AUTOSAR XML (schema 4-1-3)
standard types defined: boolean, sint8, uint16, uint32, uint8, boolean_CompuMethod, boolean_DataConstr, sint8_DataConstr, uint16_DataConstr, uint32_DataConstr, uint8_DataConstr, sint16
package /MICROSAR/Dem_swc/DataTypes
  5 x impl type:
    Dem_DebounceResetStatusType: compu {0=DEM_DEBOUNCE_STATUS_FREEZE, 1=DEM_DEBOUNCE_STATUS_RESET}, range raw 0..255, implementation-data-type=ImplementationDataTypes/uint8
    Dem_DTCFormatType: compu {0=DEM_DTC_FORMAT_OBD, 1=DEM_DTC_FORMAT_UDS, 2=DEM_DTC_FORMAT_J1939}, range raw 0..255, implementation-data-type=ImplementationDataTypes/uint8
    Dem_EventStatusType:
      compu {0=DEM_EVENT_STATUS_PASSED, 1=DEM_EVENT_STATUS_FAILED, 2=DEM_EVENT_STATUS_PREPASSED, 3=DEM_EVENT_STATUS_PREFAILED, 4=DEM_EVENT_STATUS_FDC_THRESHOLD_REACHED, 5=DEM_EVENT_STATUS_PASSED_CONDITIONS_NOT_FULFILLED, 6=DEM_EVENT_STATUS_FAILED_CONDITIONS_NOT_FULFILLED, 7=DEM_EVENT_STATUS_PREPASSED_CONDITIONS_NOT_FULFILLED, 8=DEM_EVENT_STATUS_PREFAILED_CONDITIONS_NOT_FULFILLED}
      range raw 0..255
      implementation-data-type=ImplementationDataTypes/uint8
    Dem_MaxDataValueType: category=ARRAY, sw-calibration-access=READ-ONLY
      element Dem_MaxDataValueTypeElement: array-size=4, array-size-semantics=FIXED-SIZE, implementation-data-type=ImplementationDataTypes/uint8
    Dem_UdsStatusByteType:
      compu {mask 1: 1=DEM_UDS_STATUS_TF (bit 0: TestFailed), mask 2: 2=DEM_UDS_STATUS_TFTOC (bit 1: TestFailedThisOperationCycle), mask 4: 4=DEM_UDS_STATUS_PDTC (bit 2: PendingDTC), mask 8: 8=DEM_UDS_STATUS_CDTC (bit 3: ConfirmedDTC), mask 16: 16=DEM_UDS_STATUS_TNCSLC (bit 4: TestNotCompletedSinceLastClear), mask 32: 32=DEM_UDS_STATUS_TFSLC (bit 5: TestFailedSinceLastClear), mask 64: 64=DEM_UDS_STATUS_TNCTOC (bit 6: TestNotCompletedThisOperationCycle), mask 128: 128=DEM_UDS_STATUS_WIR (bit 7: WarningIndicatorRequested)}
      range raw 0..255
      implementation-data-type=ImplementationDataTypes/uint8
package /MICROSAR/Dem_swc/Interfaces
  client server interface DiagnosticMonitor: is-service=true, service-kind=DIAGNOSTIC-EVENT-MANAGER
    11 x operation:
      GetDTCOfEvent: possible-error=[DEM_E_NO_DTC_AVAILABLE, DiagnosticMonitor/E_NOT_OK]
        arg DTCFormat: type=Dem_DTCFormatType, direction=IN, server-argument-impl-policy=USE-ARGUMENT-TYPE
        arg DTCOfEvent: type=ImplementationDataTypes/uint32, direction=OUT, server-argument-impl-policy=USE-ARGUMENT-TYPE
      GetEventExtendedDataRecordEx: possible-error=[DEM_BUFFER_TOO_SMALL, DEM_NO_SUCH_ELEMENT, DiagnosticMonitor/E_NOT_OK]
        arg RecordNumber: type=ImplementationDataTypes/uint8, direction=IN, server-argument-impl-policy=USE-ARGUMENT-TYPE
        arg DestBuffer: type=Dem_MaxDataValueType, direction=OUT, server-argument-impl-policy=USE-ARGUMENT-TYPE
        arg BufSize: type=ImplementationDataTypes/uint16, direction=INOUT, server-argument-impl-policy=USE-ARGUMENT-TYPE
      GetEventFailed: possible-error=DiagnosticMonitor/E_NOT_OK
        arg EventFailed: type=ImplementationDataTypes/boolean, direction=OUT, server-argument-impl-policy=USE-ARGUMENT-TYPE
      GetEventFreezeFrameDataEx: possible-error=[DEM_BUFFER_TOO_SMALL, DEM_NO_SUCH_ELEMENT, DiagnosticMonitor/E_NOT_OK]
        4 x arg, all with server-argument-impl-policy=USE-ARGUMENT-TYPE:
          RecordNumber: type=ImplementationDataTypes/uint8, direction=IN
          DataId: type=ImplementationDataTypes/uint16, direction=IN
          DestBuffer: type=Dem_MaxDataValueType, direction=OUT
          BufSize: type=ImplementationDataTypes/uint16, direction=INOUT
      GetEventStatus: possible-error=DiagnosticMonitor/E_NOT_OK
        arg UDSStatusByte: type=Dem_UdsStatusByteType, direction=OUT, server-argument-impl-policy=USE-ARGUMENT-TYPE
      GetEventTested: possible-error=DiagnosticMonitor/E_NOT_OK
        arg EventTested: type=ImplementationDataTypes/boolean, direction=OUT, server-argument-impl-policy=USE-ARGUMENT-TYPE
      GetEventUdsStatus: possible-error=DiagnosticMonitor/E_NOT_OK
        arg UDSStatusByte: type=Dem_UdsStatusByteType, direction=OUT, server-argument-impl-policy=USE-ARGUMENT-TYPE
      GetFaultDetectionCounter: possible-error=[DEM_E_NO_FDC_AVAILABLE, DiagnosticMonitor/E_NOT_OK]
        arg FaultDetectionCounter: type=sint8, direction=OUT, server-argument-impl-policy=USE-ARGUMENT-TYPE
      ResetEventDebounceStatus: possible-error=DiagnosticMonitor/E_NOT_OK
        arg DebounceResetStatus: type=Dem_DebounceResetStatusType, direction=IN, server-argument-impl-policy=USE-ARGUMENT-TYPE
      ResetEventStatus: possible-error=DiagnosticMonitor/E_NOT_OK
      SetEventStatus: possible-error=DiagnosticMonitor/E_NOT_OK
        arg EventStatus: type=Dem_EventStatusType, direction=IN, server-argument-impl-policy=USE-ARGUMENT-TYPE
    5 x error:
      DEM_BUFFER_TOO_SMALL: error-code=21
      DEM_E_NO_DTC_AVAILABLE: error-code=10
      DEM_E_NO_FDC_AVAILABLE: error-code=14
      DEM_NO_SUCH_ELEMENT: error-code=48
      E_NOT_OK: error-code=1
package /UAES/ASW/ApplicationDataTypes
  app type Fac_q0p001_u16: category=VALUE, sw-calibration-access=READ-WRITE, compu {phys=raw*0.001}, range phys 0..65.535
package /UAES/ASW/CompuMethods
  compu method CM_boolean: 0=FALSE, 1=TRUE
package /UAES/ASW/DataConstrs
  range DC_boolean: raw 0..1
  range DC_sint16: raw -32768..32767
  range DC_uint16: raw 0..65535
  range DC_uint32: raw 0..4294967295
  range DC_uint8: raw 0..255
package /UAES/ASW/DataTypeMappingSets
  data type mapping set DTMS_SuctnDoor_DD: data-type-map{application-data-type=Fac_q0p001_u16, implementation-data-type=ImplementationDataTypes/uint16}
package /UAES/ASW/PortInterfaces
  5 x client server interface:
    IoHwAb_HbrModCtrl
      operation Hbr_SetMod: possible-error=IoHwAb_HbrModCtrl/E_NOT_OK
        arg id_u16: type=ImplementationDataTypes/uint16, direction=IN, server-argument-impl-policy=USE-ARGUMENT-TYPE
        arg mod_u8: type=ImplementationDataTypes/uint8, direction=IN, server-argument-impl-policy=USE-ARGUMENT-TYPE
      error E_NOT_OK: error-code=1
    IoHwAb_HbrPwm
      operation Hbr_SetDuty: possible-error=IoHwAb_HbrPwm/E_NOT_OK
        arg id_u16: type=ImplementationDataTypes/uint16, direction=IN, server-argument-impl-policy=USE-ARGUMENT-TYPE
        arg duty_u16: type=ImplementationDataTypes/uint16, direction=IN, server-argument-impl-policy=USE-ARGUMENT-TYPE
      operation Hbr_SetPerd: possible-error=IoHwAb_HbrPwm/E_NOT_OK
        arg id_u16: type=ImplementationDataTypes/uint16, direction=IN, server-argument-impl-policy=USE-ARGUMENT-TYPE
        arg perd_u32: type=ImplementationDataTypes/uint32, direction=IN, server-argument-impl-policy=USE-ARGUMENT-TYPE
      operation Hbr_SetPerdAndDuty: possible-error=IoHwAb_HbrPwm/E_NOT_OK
        arg id_u16: type=ImplementationDataTypes/uint16, direction=IN, server-argument-impl-policy=USE-ARGUMENT-TYPE
        arg perd_u32: type=ImplementationDataTypes/uint32, direction=IN, server-argument-impl-policy=USE-ARGUMENT-TYPE
        arg duty_u16: type=ImplementationDataTypes/uint16, direction=IN, server-argument-impl-policy=USE-ARGUMENT-TYPE
      error E_NOT_OK: error-code=1
    IoHwAb_IoDiagHbr
      operation Hbr_Get: possible-error=IoHwAb_IoDiagHbr/E_NOT_OK
        arg id_u16: type=ImplementationDataTypes/uint16, direction=IN, server-argument-impl-policy=USE-ARGUMENT-TYPE
        arg val_u32: type=ImplementationDataTypes/uint32, direction=OUT, server-argument-impl-policy=USE-ARGUMENT-TYPE
      error E_NOT_OK: error-code=1
    IoHwAb_IoSigAdc
      operation Adc_Get: possible-error=IoHwAb_IoSigAdc/E_NOT_OK
        arg id_u16: type=ImplementationDataTypes/uint16, direction=IN, server-argument-impl-policy=USE-ARGUMENT-TYPE
        arg val_s16: type=sint16, direction=OUT, server-argument-impl-policy=USE-ARGUMENT-TYPE
      operation AdcFac_Get: possible-error=IoHwAb_IoSigAdc/E_NOT_OK
        arg id_u16: type=ImplementationDataTypes/uint16, direction=IN, server-argument-impl-policy=USE-ARGUMENT-TYPE
        arg val_s16: type=sint16, direction=OUT, server-argument-impl-policy=USE-ARGUMENT-TYPE
      operation AdcVRMBatt_Get: possible-error=IoHwAb_IoSigAdc/E_NOT_OK
        arg id_u16: type=ImplementationDataTypes/uint16, direction=IN, server-argument-impl-policy=USE-ARGUMENT-TYPE
        arg val_u8: type=ImplementationDataTypes/uint8, direction=OUT, server-argument-impl-policy=USE-ARGUMENT-TYPE
      error E_NOT_OK: error-code=1
    IoHwAb_IoSigDio
      operation Di_Get: possible-error=IoHwAb_IoSigDio/E_NOT_OK
        arg id_u16: type=ImplementationDataTypes/uint16, direction=IN, server-argument-impl-policy=USE-ARGUMENT-TYPE
        arg val_u8: type=ImplementationDataTypes/uint8, direction=OUT, server-argument-impl-policy=USE-ARGUMENT-TYPE
      operation Do_Set: possible-error=IoHwAb_IoSigDio/E_NOT_OK
        arg id_u16: type=ImplementationDataTypes/uint16, direction=IN, server-argument-impl-policy=USE-ARGUMENT-TYPE
        arg val_u8: type=ImplementationDataTypes/uint8, direction=IN, server-argument-impl-policy=USE-ARGUMENT-TYPE
      error E_NOT_OK: error-code=1
  36 x sender receiver interface:
    BattU_buExcdLrgRng: invalidation-policy{data-element=BattU_buExcdLrgRng/Val, handle-invalid=DONT-INVALIDATE}
      data Val: sw-calibration-access=READ-ONLY, type=ImplementationDataTypes/boolean
    BattU_buExcdSmallRng: invalidation-policy{data-element=BattU_buExcdSmallRng/Val, handle-invalid=DONT-INVALIDATE}
      data Val: sw-calibration-access=READ-ONLY, type=ImplementationDataTypes/boolean
    BattU_VrmFac1: invalidation-policy{data-element=BattU_VrmFac1/Val, handle-invalid=DONT-INVALIDATE}
      data Val: sw-calibration-access=READ-ONLY, type=Fac_q0p001_u16
    BattU_VrmFac2: invalidation-policy{data-element=BattU_VrmFac2/Val, handle-invalid=DONT-INVALIDATE}
      data Val: sw-calibration-access=READ-ONLY, type=Fac_q0p001_u16
    BattU_VrmFac3: invalidation-policy{data-element=BattU_VrmFac3/Val, handle-invalid=DONT-INVALIDATE}
      data Val: sw-calibration-access=READ-ONLY, type=Fac_q0p001_u16
    gLock_u8DiagEnbCnd: invalidation-policy{data-element=gLock_u8DiagEnbCnd/Val, handle-invalid=DONT-INVALIDATE}
      data Val: sw-calibration-access=READ-ONLY, type=ImplementationDataTypes/uint8
    gLockCtrl_u8FLDoorElecCinchMotorOutput: invalidation-policy{data-element=gLockCtrl_u8FLDoorElecCinchMotorOutput/Val, handle-invalid=DONT-INVALIDATE}
      data Val: sw-calibration-access=READ-ONLY, type=ImplementationDataTypes/uint8
    gLockCtrl_u8FLDoorElecCinchPWMOutput: invalidation-policy{data-element=gLockCtrl_u8FLDoorElecCinchPWMOutput/Val, handle-invalid=DONT-INVALIDATE}
      data Val: sw-calibration-access=READ-ONLY, type=ImplementationDataTypes/uint8
    gLockCtrl_u8FRDoorElecCinchMotorOutput: invalidation-policy{data-element=gLockCtrl_u8FRDoorElecCinchMotorOutput/Val, handle-invalid=DONT-INVALIDATE}
      data Val: sw-calibration-access=READ-ONLY, type=ImplementationDataTypes/uint8
    gLockCtrl_u8FRDoorElecCinchPWMOutput: invalidation-policy{data-element=gLockCtrl_u8FRDoorElecCinchPWMOutput/Val, handle-invalid=DONT-INVALIDATE}
      data Val: sw-calibration-access=READ-ONLY, type=ImplementationDataTypes/uint8
    gLockCtrl_u8RLDoorElecCinchMotorOutput: invalidation-policy{data-element=gLockCtrl_u8RLDoorElecCinchMotorOutput/Val, handle-invalid=DONT-INVALIDATE}
      data Val: sw-calibration-access=READ-ONLY, type=ImplementationDataTypes/uint8
    gLockCtrl_u8RLDoorElecCinchPWMOutput: invalidation-policy{data-element=gLockCtrl_u8RLDoorElecCinchPWMOutput/Val, handle-invalid=DONT-INVALIDATE}
      data Val: sw-calibration-access=READ-ONLY, type=ImplementationDataTypes/uint8
    gLockCtrl_u8RRDoorElecCinchMotorOutput: invalidation-policy{data-element=gLockCtrl_u8RRDoorElecCinchMotorOutput/Val, handle-invalid=DONT-INVALIDATE}
      data Val: sw-calibration-access=READ-ONLY, type=ImplementationDataTypes/uint8
    gLockCtrl_u8RRDoorElecCinchPWMOutput: invalidation-policy{data-element=gLockCtrl_u8RRDoorElecCinchPWMOutput/Val, handle-invalid=DONT-INVALIDATE}
      data Val: sw-calibration-access=READ-ONLY, type=ImplementationDataTypes/uint8
    gSuctnDoor_bFLCinchMotorMinusSt: invalidation-policy{data-element=gSuctnDoor_bFLCinchMotorMinusSt/Val, handle-invalid=DONT-INVALIDATE}
      data Val: sw-calibration-access=READ-ONLY, type=ImplementationDataTypes/boolean
    gSuctnDoor_bFLCinchMotorPlusSt: invalidation-policy{data-element=gSuctnDoor_bFLCinchMotorPlusSt/Val, handle-invalid=DONT-INVALIDATE}
      data Val: sw-calibration-access=READ-ONLY, type=ImplementationDataTypes/boolean
    gSuctnDoor_bFLCinchReset: invalidation-policy{data-element=gSuctnDoor_bFLCinchReset/Val, handle-invalid=DONT-INVALIDATE}
      data Val: sw-calibration-access=READ-ONLY, type=ImplementationDataTypes/boolean
    gSuctnDoor_bFLInPwrRelsSwt: invalidation-policy{data-element=gSuctnDoor_bFLInPwrRelsSwt/Val, handle-invalid=DONT-INVALIDATE}
      data Val: sw-calibration-access=READ-ONLY, type=ImplementationDataTypes/boolean
    gSuctnDoor_bFLPAWL: invalidation-policy{data-element=gSuctnDoor_bFLPAWL/Val, handle-invalid=DONT-INVALIDATE}
      data Val: sw-calibration-access=READ-ONLY, type=ImplementationDataTypes/boolean
    gSuctnDoor_bFLSecLockFbSt: invalidation-policy{data-element=gSuctnDoor_bFLSecLockFbSt/Val, handle-invalid=DONT-INVALIDATE}
      data Val: sw-calibration-access=READ-ONLY, type=ImplementationDataTypes/boolean
    gSuctnDoor_bFRCinchMotorMinusSt: invalidation-policy{data-element=gSuctnDoor_bFRCinchMotorMinusSt/Val, handle-invalid=DONT-INVALIDATE}
      data Val: sw-calibration-access=READ-ONLY, type=ImplementationDataTypes/boolean
    gSuctnDoor_bFRCinchMotorPlusSt: invalidation-policy{data-element=gSuctnDoor_bFRCinchMotorPlusSt/Val, handle-invalid=DONT-INVALIDATE}
      data Val: sw-calibration-access=READ-ONLY, type=ImplementationDataTypes/boolean
    gSuctnDoor_bFRCinchReset: invalidation-policy{data-element=gSuctnDoor_bFRCinchReset/Val, handle-invalid=DONT-INVALIDATE}
      data Val: sw-calibration-access=READ-ONLY, type=ImplementationDataTypes/boolean
    gSuctnDoor_bFRElecDoorCloseSwt: invalidation-policy{data-element=gSuctnDoor_bFRElecDoorCloseSwt/Val, handle-invalid=DONT-INVALIDATE}
      data Val: sw-calibration-access=READ-ONLY, type=ImplementationDataTypes/boolean
    gSuctnDoor_bFROutPwrRelsSwt: invalidation-policy{data-element=gSuctnDoor_bFROutPwrRelsSwt/Val, handle-invalid=DONT-INVALIDATE}
      data Val: sw-calibration-access=READ-ONLY, type=ImplementationDataTypes/boolean
    gSuctnDoor_bFRPAWL: invalidation-policy{data-element=gSuctnDoor_bFRPAWL/Val, handle-invalid=DONT-INVALIDATE}
      data Val: sw-calibration-access=READ-ONLY, type=ImplementationDataTypes/boolean
    gSuctnDoor_bFRSecLockFbSt: invalidation-policy{data-element=gSuctnDoor_bFRSecLockFbSt/Val, handle-invalid=DONT-INVALIDATE}
      data Val: sw-calibration-access=READ-ONLY, type=ImplementationDataTypes/boolean
    gSuctnDoor_bRLCinchReset: invalidation-policy{data-element=gSuctnDoor_bRLCinchReset/Val, handle-invalid=DONT-INVALIDATE}
      data Val: sw-calibration-access=READ-ONLY, type=ImplementationDataTypes/boolean
    gSuctnDoor_bRLInPwrRelsSwt: invalidation-policy{data-element=gSuctnDoor_bRLInPwrRelsSwt/Val, handle-invalid=DONT-INVALIDATE}
      data Val: sw-calibration-access=READ-ONLY, type=ImplementationDataTypes/boolean
    gSuctnDoor_bRLSecLockFbSt: invalidation-policy{data-element=gSuctnDoor_bRLSecLockFbSt/Val, handle-invalid=DONT-INVALIDATE}
      data Val: sw-calibration-access=READ-ONLY, type=ImplementationDataTypes/boolean
    gSuctnDoor_bRRCinchReset: invalidation-policy{data-element=gSuctnDoor_bRRCinchReset/Val, handle-invalid=DONT-INVALIDATE}
      data Val: sw-calibration-access=READ-ONLY, type=ImplementationDataTypes/boolean
    gSuctnDoor_bRRInPwrRlesSwt: invalidation-policy{data-element=gSuctnDoor_bRRInPwrRlesSwt/Val, handle-invalid=DONT-INVALIDATE}
      data Val: sw-calibration-access=READ-ONLY, type=ImplementationDataTypes/boolean
    gSuctnDoor_bRRSecLockFbSt: invalidation-policy{data-element=gSuctnDoor_bRRSecLockFbSt/Val, handle-invalid=DONT-INVALIDATE}
      data Val: sw-calibration-access=READ-ONLY, type=ImplementationDataTypes/boolean
    gSuctnDoor_u8FLCinchMotorPs: invalidation-policy{data-element=gSuctnDoor_u8FLCinchMotorPs/Val, handle-invalid=DONT-INVALIDATE}
      data Val: sw-calibration-access=READ-ONLY, type=ImplementationDataTypes/uint8
    gSuctnDoor_u8FLElecDoorSwt: invalidation-policy{data-element=gSuctnDoor_u8FLElecDoorSwt/Val, handle-invalid=DONT-INVALIDATE}
      data Val: sw-calibration-access=READ-ONLY, type=ImplementationDataTypes/uint8
    gSuctnDoor_u8FRCinchMotorPs: invalidation-policy{data-element=gSuctnDoor_u8FRCinchMotorPs/Val, handle-invalid=DONT-INVALIDATE}
      data Val: sw-calibration-access=READ-ONLY, type=ImplementationDataTypes/uint8
package /UAES/ASW/SwComponentTypes
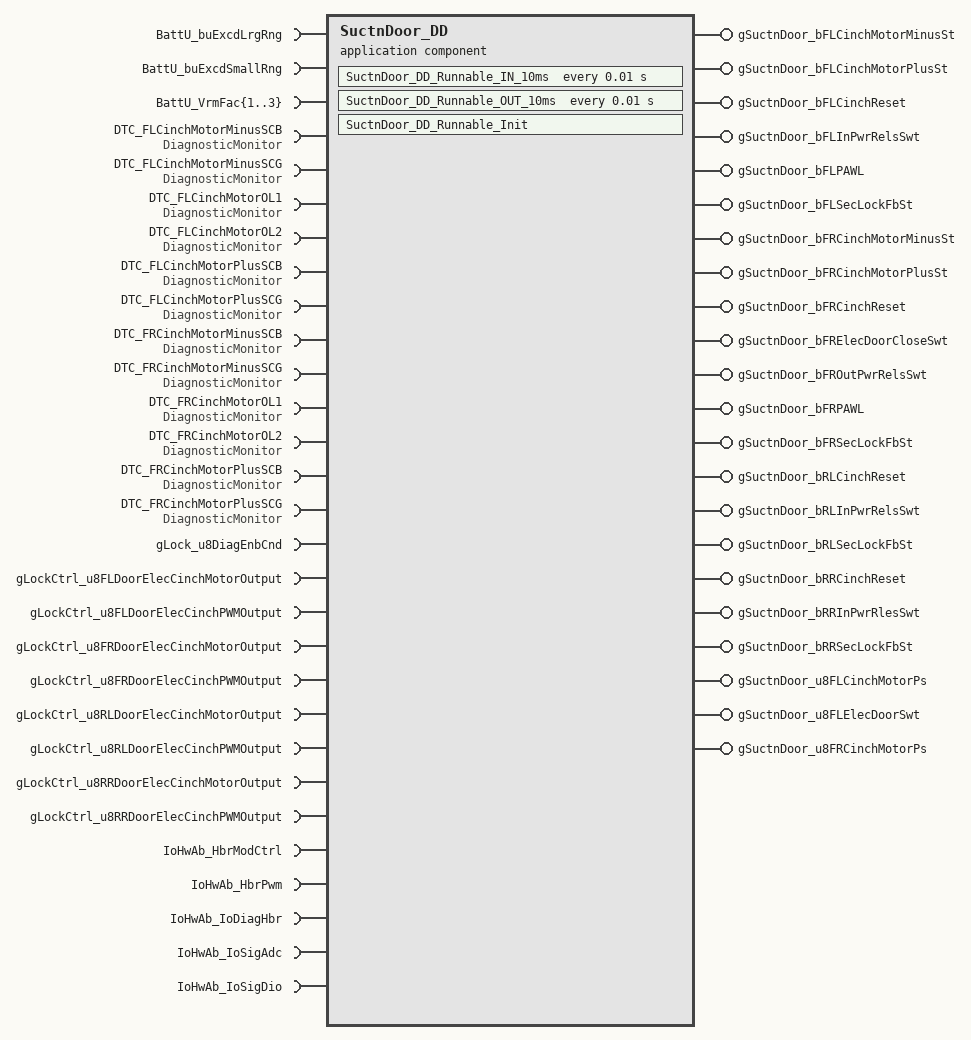
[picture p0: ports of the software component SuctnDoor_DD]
  application sw component type SuctnDoor_DD
    22 x provide port:
      gSuctnDoor_bFLCinchMotorMinusSt: nonqueued-sender-com-spec{data-element=gSuctnDoor_bFLCinchMotorMinusSt/Val, init-value=0}, provided-interface=gSuctnDoor_bFLCinchMotorMinusSt
      gSuctnDoor_bFLCinchMotorPlusSt: nonqueued-sender-com-spec{data-element=gSuctnDoor_bFLCinchMotorPlusSt/Val, init-value=0}, provided-interface=gSuctnDoor_bFLCinchMotorPlusSt
      gSuctnDoor_bFLCinchReset: nonqueued-sender-com-spec{data-element=gSuctnDoor_bFLCinchReset/Val, init-value=0}, provided-interface=gSuctnDoor_bFLCinchReset
      gSuctnDoor_bFLInPwrRelsSwt: nonqueued-sender-com-spec{data-element=gSuctnDoor_bFLInPwrRelsSwt/Val, init-value=0}, provided-interface=gSuctnDoor_bFLInPwrRelsSwt
      gSuctnDoor_bFLPAWL: nonqueued-sender-com-spec{data-element=gSuctnDoor_bFLPAWL/Val, init-value=0}, provided-interface=gSuctnDoor_bFLPAWL
      gSuctnDoor_bFLSecLockFbSt: nonqueued-sender-com-spec{data-element=gSuctnDoor_bFLSecLockFbSt/Val, init-value=0}, provided-interface=gSuctnDoor_bFLSecLockFbSt
      gSuctnDoor_bFRCinchMotorMinusSt: nonqueued-sender-com-spec{data-element=gSuctnDoor_bFRCinchMotorMinusSt/Val, init-value=0}, provided-interface=gSuctnDoor_bFRCinchMotorMinusSt
      gSuctnDoor_bFRCinchMotorPlusSt: nonqueued-sender-com-spec{data-element=gSuctnDoor_bFRCinchMotorPlusSt/Val, init-value=0}, provided-interface=gSuctnDoor_bFRCinchMotorPlusSt
      gSuctnDoor_bFRCinchReset: nonqueued-sender-com-spec{data-element=gSuctnDoor_bFRCinchReset/Val, init-value=0}, provided-interface=gSuctnDoor_bFRCinchReset
      gSuctnDoor_bFRElecDoorCloseSwt: nonqueued-sender-com-spec{data-element=gSuctnDoor_bFRElecDoorCloseSwt/Val, init-value=0}, provided-interface=gSuctnDoor_bFRElecDoorCloseSwt
      gSuctnDoor_bFROutPwrRelsSwt: nonqueued-sender-com-spec{data-element=gSuctnDoor_bFROutPwrRelsSwt/Val, init-value=0}, provided-interface=gSuctnDoor_bFROutPwrRelsSwt
      gSuctnDoor_bFRPAWL: nonqueued-sender-com-spec{data-element=gSuctnDoor_bFRPAWL/Val, init-value=0}, provided-interface=gSuctnDoor_bFRPAWL
      gSuctnDoor_bFRSecLockFbSt: nonqueued-sender-com-spec{data-element=gSuctnDoor_bFRSecLockFbSt/Val, init-value=0}, provided-interface=gSuctnDoor_bFRSecLockFbSt
      gSuctnDoor_bRLCinchReset: nonqueued-sender-com-spec{data-element=gSuctnDoor_bRLCinchReset/Val, init-value=0}, provided-interface=gSuctnDoor_bRLCinchReset
      gSuctnDoor_bRLInPwrRelsSwt: nonqueued-sender-com-spec{data-element=gSuctnDoor_bRLInPwrRelsSwt/Val, init-value=0}, provided-interface=gSuctnDoor_bRLInPwrRelsSwt
      gSuctnDoor_bRLSecLockFbSt: nonqueued-sender-com-spec{data-element=gSuctnDoor_bRLSecLockFbSt/Val, init-value=0}, provided-interface=gSuctnDoor_bRLSecLockFbSt
      gSuctnDoor_bRRCinchReset: nonqueued-sender-com-spec{data-element=gSuctnDoor_bRRCinchReset/Val, init-value=0}, provided-interface=gSuctnDoor_bRRCinchReset
      gSuctnDoor_bRRInPwrRlesSwt: nonqueued-sender-com-spec{data-element=gSuctnDoor_bRRInPwrRlesSwt/Val, init-value=0}, provided-interface=gSuctnDoor_bRRInPwrRlesSwt
      gSuctnDoor_bRRSecLockFbSt: nonqueued-sender-com-spec{data-element=gSuctnDoor_bRRSecLockFbSt/Val, init-value=0}, provided-interface=gSuctnDoor_bRRSecLockFbSt
      gSuctnDoor_u8FLCinchMotorPs: nonqueued-sender-com-spec{data-element=gSuctnDoor_u8FLCinchMotorPs/Val, init-value=0}, provided-interface=gSuctnDoor_u8FLCinchMotorPs
      gSuctnDoor_u8FLElecDoorSwt: nonqueued-sender-com-spec{data-element=gSuctnDoor_u8FLElecDoorSwt/Val, init-value=ComSpec0e782811_d4aa58b4acc01151:0}, provided-interface=gSuctnDoor_u8FLElecDoorSwt
      gSuctnDoor_u8FRCinchMotorPs: nonqueued-sender-com-spec{data-element=gSuctnDoor_u8FRCinchMotorPs/Val, init-value=0}, provided-interface=gSuctnDoor_u8FRCinchMotorPs
    31 x require port:
      BattU_buExcdLrgRng: nonqueued-receiver-com-spec{data-element=BattU_buExcdLrgRng/Val, filter=data-filter-type=ALWAYS, init-value=ComSpec1079bfe5_5cfdb696913237dd:0}, required-interface=BattU_buExcdLrgRng
      BattU_buExcdSmallRng: nonqueued-receiver-com-spec{data-element=BattU_buExcdSmallRng/Val, filter=data-filter-type=ALWAYS, init-value=ComSpecfebe3aa4_0d298b533ebf4b24:0}, required-interface=BattU_buExcdSmallRng
      BattU_VrmFac{1..3}: nonqueued-receiver-com-spec{data-element=BattU_VrmFac{1..3}/Val, filter=data-filter-type=ALWAYS, init-value=0}, required-interface=BattU_VrmFac{1..3}
      DTC_FLCinchMotorMinusSCB: required-interface=DiagnosticMonitor
        required-com-specs:
          GetDTCOfEvent
          GetEventExtendedDataRecordEx
          GetEventFailed
          GetEventFreezeFrameDataEx
          GetEventStatus
          GetEventTested
          GetEventUdsStatus
          GetFaultDetectionCounter
          ResetEventDebounceStatus
          ResetEventStatus
          SetEventStatus
      DTC_FLCinchMotorMinusSCG: required-interface=DiagnosticMonitor
        required-com-specs:
          GetDTCOfEvent
          GetEventExtendedDataRecordEx
          GetEventFailed
          GetEventFreezeFrameDataEx
          GetEventStatus
          GetEventTested
          GetEventUdsStatus
          GetFaultDetectionCounter
          ResetEventDebounceStatus
          ResetEventStatus
          SetEventStatus
      DTC_FLCinchMotorOL1: required-interface=DiagnosticMonitor
        required-com-specs:
          GetDTCOfEvent
          GetEventExtendedDataRecordEx
          GetEventFailed
          GetEventFreezeFrameDataEx
          GetEventStatus
          GetEventTested
          GetEventUdsStatus
          GetFaultDetectionCounter
          ResetEventDebounceStatus
          ResetEventStatus
          SetEventStatus
      DTC_FLCinchMotorOL2: required-interface=DiagnosticMonitor
        required-com-specs:
          GetDTCOfEvent
          GetEventExtendedDataRecordEx
          GetEventFailed
          GetEventFreezeFrameDataEx
          GetEventStatus
          GetEventTested
          GetEventUdsStatus
          GetFaultDetectionCounter
          ResetEventDebounceStatus
          ResetEventStatus
          SetEventStatus
      DTC_FLCinchMotorPlusSCB: required-interface=DiagnosticMonitor
        required-com-specs:
          GetDTCOfEvent
          GetEventExtendedDataRecordEx
          GetEventFailed
          GetEventFreezeFrameDataEx
          GetEventStatus
          GetEventTested
          GetEventUdsStatus
          GetFaultDetectionCounter
          ResetEventDebounceStatus
          ResetEventStatus
          SetEventStatus
      DTC_FLCinchMotorPlusSCG: required-interface=DiagnosticMonitor
        required-com-specs:
          GetDTCOfEvent
          GetEventExtendedDataRecordEx
          GetEventFailed
          GetEventFreezeFrameDataEx
          GetEventStatus
          GetEventTested
          GetEventUdsStatus
          GetFaultDetectionCounter
          ResetEventDebounceStatus
          ResetEventStatus
          SetEventStatus
      DTC_FRCinchMotorMinusSCB: required-interface=DiagnosticMonitor
        required-com-specs:
          GetDTCOfEvent
          GetEventExtendedDataRecordEx
          GetEventFailed
          GetEventFreezeFrameDataEx
          GetEventStatus
          GetEventTested
          GetEventUdsStatus
          GetFaultDetectionCounter
          ResetEventDebounceStatus
          ResetEventStatus
          SetEventStatus
      DTC_FRCinchMotorMinusSCG: required-interface=DiagnosticMonitor
        required-com-specs:
          GetDTCOfEvent
          GetEventExtendedDataRecordEx
          GetEventFailed
          GetEventFreezeFrameDataEx
          GetEventStatus
          GetEventTested
          GetEventUdsStatus
          GetFaultDetectionCounter
          ResetEventDebounceStatus
          ResetEventStatus
          SetEventStatus
      DTC_FRCinchMotorOL1: required-interface=DiagnosticMonitor
        required-com-specs:
          GetDTCOfEvent
          GetEventExtendedDataRecordEx
          GetEventFailed
          GetEventFreezeFrameDataEx
          GetEventStatus
          GetEventTested
          GetEventUdsStatus
          GetFaultDetectionCounter
          ResetEventDebounceStatus
          ResetEventStatus
          SetEventStatus
      DTC_FRCinchMotorOL2: required-interface=DiagnosticMonitor
        required-com-specs:
          GetDTCOfEvent
          GetEventExtendedDataRecordEx
          GetEventFailed
          GetEventFreezeFrameDataEx
          GetEventStatus
          GetEventTested
          GetEventUdsStatus
          GetFaultDetectionCounter
          ResetEventDebounceStatus
          ResetEventStatus
          SetEventStatus
      DTC_FRCinchMotorPlusSCB: required-interface=DiagnosticMonitor
        required-com-specs:
          GetDTCOfEvent
          GetEventExtendedDataRecordEx
          GetEventFailed
          GetEventFreezeFrameDataEx
          GetEventStatus
          GetEventTested
          GetEventUdsStatus
          GetFaultDetectionCounter
          ResetEventDebounceStatus
          ResetEventStatus
          SetEventStatus
      DTC_FRCinchMotorPlusSCG: required-interface=DiagnosticMonitor
        required-com-specs:
          GetDTCOfEvent
          GetEventExtendedDataRecordEx
          GetEventFailed
          GetEventFreezeFrameDataEx
          GetEventStatus
          GetEventTested
          GetEventUdsStatus
          GetFaultDetectionCounter
          ResetEventDebounceStatus
          ResetEventStatus
          SetEventStatus
      gLock_u8DiagEnbCnd: nonqueued-receiver-com-spec{data-element=gLock_u8DiagEnbCnd/Val, filter=data-filter-type=ALWAYS, init-value=0}, required-interface=gLock_u8DiagEnbCnd
      gLockCtrl_u8FLDoorElecCinchMotorOutput: nonqueued-receiver-com-spec{data-element=gLockCtrl_u8FLDoorElecCinchMotorOutput/Val, filter=data-filter-type=ALWAYS, init-value=0}, required-interface=gLockCtrl_u8FLDoorElecCinchMotorOutput
      gLockCtrl_u8FLDoorElecCinchPWMOutput: nonqueued-receiver-com-spec{data-element=gLockCtrl_u8FLDoorElecCinchPWMOutput/Val, filter=data-filter-type=ALWAYS, init-value=0}, required-interface=gLockCtrl_u8FLDoorElecCinchPWMOutput
      gLockCtrl_u8FRDoorElecCinchMotorOutput: nonqueued-receiver-com-spec{data-element=gLockCtrl_u8FRDoorElecCinchMotorOutput/Val, filter=data-filter-type=ALWAYS, init-value=0}, required-interface=gLockCtrl_u8FRDoorElecCinchMotorOutput
      gLockCtrl_u8FRDoorElecCinchPWMOutput: nonqueued-receiver-com-spec{data-element=gLockCtrl_u8FRDoorElecCinchPWMOutput/Val, filter=data-filter-type=ALWAYS, init-value=0}, required-interface=gLockCtrl_u8FRDoorElecCinchPWMOutput
      gLockCtrl_u8RLDoorElecCinchMotorOutput: nonqueued-receiver-com-spec{data-element=gLockCtrl_u8RLDoorElecCinchMotorOutput/Val, filter=data-filter-type=ALWAYS, init-value=0}, required-interface=gLockCtrl_u8RLDoorElecCinchMotorOutput
      gLockCtrl_u8RLDoorElecCinchPWMOutput: nonqueued-receiver-com-spec{data-element=gLockCtrl_u8RLDoorElecCinchPWMOutput/Val, filter=data-filter-type=ALWAYS, init-value=0}, required-interface=gLockCtrl_u8RLDoorElecCinchPWMOutput
      gLockCtrl_u8RRDoorElecCinchMotorOutput: nonqueued-receiver-com-spec{data-element=gLockCtrl_u8RRDoorElecCinchMotorOutput/Val, filter=data-filter-type=ALWAYS, init-value=0}, required-interface=gLockCtrl_u8RRDoorElecCinchMotorOutput
      gLockCtrl_u8RRDoorElecCinchPWMOutput: nonqueued-receiver-com-spec{data-element=gLockCtrl_u8RRDoorElecCinchPWMOutput/Val, filter=data-filter-type=ALWAYS, init-value=0}, required-interface=gLockCtrl_u8RRDoorElecCinchPWMOutput
      IoHwAb_HbrModCtrl: client-com-spec=Hbr_SetMod, required-interface=IoHwAb_HbrModCtrl
      IoHwAb_HbrPwm: required-com-specs=[Hbr_SetDuty, Hbr_SetPerd, Hbr_SetPerdAndDuty], required-interface=IoHwAb_HbrPwm
      IoHwAb_IoDiagHbr: client-com-spec=Hbr_Get, required-interface=IoHwAb_IoDiagHbr
      IoHwAb_IoSigAdc: required-com-specs=[Adc_Get, AdcFac_Get, AdcVRMBatt_Get], required-interface=IoHwAb_IoSigAdc
      IoHwAb_IoSigDio: required-com-specs=[Di_Get, Do_Set], required-interface=IoHwAb_IoSigDio
    behavior SuctnDoor_DD_InternalBehavior: data-type-mapping=DTMS_SuctnDoor_DD
      timing event TMT_SuctnDoor_DD_Runnable_IN_10ms: start-on-event=SuctnDoor_DD_Runnable_IN_10ms, period=0.01
      init event SuctnDoor_DD_InitEvent: start-on-event=SuctnDoor_DD_Runnable_Init
      timing event TMT_SuctnDoor_DD_Runnable_OUT_10ms: start-on-event=SuctnDoor_DD_Runnable_OUT_10ms, period=0.01
      runnable SuctnDoor_DD_Runnable_IN_10ms
        data-receive-point-by-arguments:
          5 x access:
            IN_BattU_buExcdSmallRng_Val: accessed-variable=BattU_buExcdSmallRng.Val
            IN_BattU_VrmFac{1..3}_Val: accessed-variable=BattU_VrmFac{1..3}.Val
            REC_BattU_buExcdLrgRng_Val: accessed-variable=BattU_buExcdLrgRng.Val
        data-send-points:
          16 x access:
            SEND_gSuctnDoor_bFLCinchReset_Val: accessed-variable=gSuctnDoor_bFLCinchReset.Val
            SEND_gSuctnDoor_bFLInPwrRelsSwt_Val: accessed-variable=gSuctnDoor_bFLInPwrRelsSwt.Val
            SEND_gSuctnDoor_bFLPAWL_Val: accessed-variable=gSuctnDoor_bFLPAWL.Val
            SEND_gSuctnDoor_bFLSecLockFbSt_Val: accessed-variable=gSuctnDoor_bFLSecLockFbSt.Val
            SEND_gSuctnDoor_bFRCinchReset_Val: accessed-variable=gSuctnDoor_bFRCinchReset.Val
            SEND_gSuctnDoor_bFRElecDoorCloseSwt_Val: accessed-variable=gSuctnDoor_bFRElecDoorCloseSwt.Val
            SEND_gSuctnDoor_bFROutPwrRelsSwt_Val: accessed-variable=gSuctnDoor_bFROutPwrRelsSwt.Val
            SEND_gSuctnDoor_bFRPAWL_Val: accessed-variable=gSuctnDoor_bFRPAWL.Val
            SEND_gSuctnDoor_bFRSecLockFbSt_Val: accessed-variable=gSuctnDoor_bFRSecLockFbSt.Val
            SEND_gSuctnDoor_bRLCinchReset_Val: accessed-variable=gSuctnDoor_bRLCinchReset.Val
            SEND_gSuctnDoor_bRLInPwrRelsSwt_Val: accessed-variable=gSuctnDoor_bRLInPwrRelsSwt.Val
            SEND_gSuctnDoor_bRLSecLockFbSt_Val: accessed-variable=gSuctnDoor_bRLSecLockFbSt.Val
            SEND_gSuctnDoor_bRRCinchReset_Val: accessed-variable=gSuctnDoor_bRRCinchReset.Val
            SEND_gSuctnDoor_bRRInPwrRlesSwt_Val: accessed-variable=gSuctnDoor_bRRInPwrRlesSwt.Val
            SEND_gSuctnDoor_bRRSecLockFbSt_Val: accessed-variable=gSuctnDoor_bRRSecLockFbSt.Val
            SEND_gSuctnDoor_u8FLElecDoorSwt_Val: accessed-variable=gSuctnDoor_u8FLElecDoorSwt.Val
        sync call SC_IoHwAb_IoSigAdc_AdcFac_Get: operation=IoHwAb_IoSigAdc.AdcFac_Get, timeout=0
        sync call SC_IoHwAb_IoSigAdc_AdcVRMBatt_Get: operation=IoHwAb_IoSigAdc.AdcVRMBatt_Get, timeout=0
        sync call SC_IoHwAb_IoSigDio_Di_Get: operation=IoHwAb_IoSigDio.Di_Get, timeout=0
      runnable SuctnDoor_DD_Runnable_Init
      runnable SuctnDoor_DD_Runnable_OUT_10ms
        data-receive-point-by-arguments:
          9 x access:
            REC_gLock_u8DiagEnaCnd_Val: accessed-variable=gLock_u8DiagEnbCnd.Val
            REC_gLockCtrl_u8FLDoorElecCinchMotorOutput_Val: accessed-variable=gLockCtrl_u8FLDoorElecCinchMotorOutput.Val
            REC_gLockCtrl_u8FLDoorElecCinchPWMOutput_Val: accessed-variable=gLockCtrl_u8FLDoorElecCinchPWMOutput.Val
            REC_gLockCtrl_u8FRDoorElecCinchMotorOutput_Val: accessed-variable=gLockCtrl_u8FRDoorElecCinchMotorOutput.Val
            REC_gLockCtrl_u8FRDoorElecCinchPWMOutput_Val: accessed-variable=gLockCtrl_u8FRDoorElecCinchPWMOutput.Val
            REC_gLockCtrl_u8RLDoorElecCinchMotorOutput_Val: accessed-variable=gLockCtrl_u8RLDoorElecCinchMotorOutput.Val
            REC_gLockCtrl_u8RLDoorElecCinchPWMOutput_Val: accessed-variable=gLockCtrl_u8RLDoorElecCinchPWMOutput.Val
            REC_gLockCtrl_u8RRDoorElecCinchMotorOutput_Val: accessed-variable=gLockCtrl_u8RRDoorElecCinchMotorOutput.Val
            REC_gLockCtrl_u8RRDoorElecCinchPWMOutput_Val: accessed-variable=gLockCtrl_u8RRDoorElecCinchPWMOutput.Val
        data-send-points:
          6 x access:
            SEND_gSuctnDoor_bFLCinchMotorMinusSt_Val: accessed-variable=gSuctnDoor_bFLCinchMotorMinusSt.Val
            SEND_gSuctnDoor_bFLCinchMotorPlusSt_Val: accessed-variable=gSuctnDoor_bFLCinchMotorPlusSt.Val
            SEND_gSuctnDoor_bFRCinchMotorMinusSt_Val: accessed-variable=gSuctnDoor_bFRCinchMotorMinusSt.Val
            SEND_gSuctnDoor_bFRCinchMotorPlusSt_Val: accessed-variable=gSuctnDoor_bFRCinchMotorPlusSt.Val
            SEND_gSuctnDoor_u8FLCinchMotorPs_Val: accessed-variable=gSuctnDoor_u8FLCinchMotorPs.Val
            SEND_gSuctnDoor_u8FRCinchMotorPs_Val: accessed-variable=gSuctnDoor_u8FRCinchMotorPs.Val
        39 x sync call:
          SC_DTC_FLCinchMotorMinusSCB_GetEventFailed: operation=DTC_FLCinchMotorMinusSCB.GetEventFailed, timeout=1E-06
          SC_DTC_FLCinchMotorMinusSCB_ResetEventDebounceStatus: operation=DTC_FLCinchMotorMinusSCB.ResetEventDebounceStatus, timeout=1E-06
          SC_DTC_FLCinchMotorMinusSCB_SetEventStatus: operation=DTC_FLCinchMotorMinusSCB.SetEventStatus, timeout=1E-06
          SC_DTC_FLCinchMotorMinusSCG_GetEventFailed: operation=DTC_FLCinchMotorMinusSCG.GetEventFailed, timeout=1E-06
          SC_DTC_FLCinchMotorMinusSCG_ResetEventDebounceStatus: operation=DTC_FLCinchMotorMinusSCG.ResetEventDebounceStatus, timeout=1E-06
          SC_DTC_FLCinchMotorMinusSCG_SetEventStatus: operation=DTC_FLCinchMotorMinusSCG.SetEventStatus, timeout=1E-06
          SC_DTC_FLCinchMotorOL1_GetEventFailed: operation=DTC_FLCinchMotorOL1.GetEventFailed, timeout=1E-06
          SC_DTC_FLCinchMotorOL1_ResetEventDebounceStatus: operation=DTC_FLCinchMotorOL1.ResetEventDebounceStatus, timeout=1E-06
          SC_DTC_FLCinchMotorOL1_SetEventStatus: operation=DTC_FLCinchMotorOL1.SetEventStatus, timeout=1E-06
          SC_DTC_FLCinchMotorOL2_GetEventFailed: operation=DTC_FLCinchMotorOL2.GetEventFailed, timeout=1E-06
          SC_DTC_FLCinchMotorOL2_ResetEventDebounceStatus: operation=DTC_FLCinchMotorOL2.ResetEventDebounceStatus, timeout=1E-06
          SC_DTC_FLCinchMotorOL2_SetEventStatus: operation=DTC_FLCinchMotorOL2.SetEventStatus, timeout=1E-06
          SC_DTC_FLCinchMotorPlusSCB_GetEventFailed: operation=DTC_FLCinchMotorPlusSCB.GetEventFailed, timeout=1E-06
          SC_DTC_FLCinchMotorPlusSCB_ResetEventDebounceStatus: operation=DTC_FLCinchMotorPlusSCB.ResetEventDebounceStatus, timeout=1E-06
          SC_DTC_FLCinchMotorPlusSCB_SetEventStatus: operation=DTC_FLCinchMotorPlusSCB.SetEventStatus, timeout=1E-06
          SC_DTC_FLCinchMotorPlusSCG_GetEventFailed: operation=DTC_FLCinchMotorPlusSCG.GetEventFailed, timeout=1E-06
          SC_DTC_FLCinchMotorPlusSCG_ResetEventDebounceStatus: operation=DTC_FLCinchMotorPlusSCG.ResetEventDebounceStatus, timeout=1E-06
          SC_DTC_FLCinchMotorPlusSCG_SetEventStatus: operation=DTC_FLCinchMotorPlusSCG.SetEventStatus, timeout=1E-06
          SC_DTC_FRCinchMotorMinusSCB_GetEventFailed: operation=DTC_FRCinchMotorMinusSCB.GetEventFailed, timeout=1E-06
          SC_DTC_FRCinchMotorMinusSCB_ResetEventDebounceStatus: operation=DTC_FRCinchMotorMinusSCB.ResetEventDebounceStatus, timeout=1E-06
          SC_DTC_FRCinchMotorMinusSCB_SetEventStatus: operation=DTC_FRCinchMotorMinusSCB.SetEventStatus, timeout=1E-06
          SC_DTC_FRCinchMotorMinusSCG_GetEventFailed: operation=DTC_FRCinchMotorMinusSCG.GetEventFailed, timeout=1E-06
          SC_DTC_FRCinchMotorMinusSCG_ResetEventDebounceStatus: operation=DTC_FRCinchMotorMinusSCG.ResetEventDebounceStatus, timeout=1E-06
          SC_DTC_FRCinchMotorMinusSCG_SetEventStatus: operation=DTC_FRCinchMotorMinusSCG.SetEventStatus, timeout=1E-06
          SC_DTC_FRCinchMotorOL1_GetEventTested: operation=DTC_FRCinchMotorOL1.GetEventTested, timeout=1E-06
          SC_DTC_FRCinchMotorOL1_ResetEventDebounceStatus: operation=DTC_FRCinchMotorOL1.ResetEventDebounceStatus, timeout=1E-06
          SC_DTC_FRCinchMotorOL1_SetEventStatus: operation=DTC_FRCinchMotorOL1.SetEventStatus, timeout=1E-06
          SC_DTC_FRCinchMotorOL2_GetEventFailed: operation=DTC_FRCinchMotorOL2.GetEventFailed, timeout=1E-06
          SC_DTC_FRCinchMotorOL2_ResetEventDebounceStatus: operation=DTC_FRCinchMotorOL2.ResetEventDebounceStatus, timeout=1E-06
          SC_DTC_FRCinchMotorOL2_SetEventStatus: operation=DTC_FRCinchMotorOL2.SetEventStatus, timeout=1E-06
          SC_DTC_FRCinchMotorPlusSCB_GetEventFailed: operation=DTC_FRCinchMotorPlusSCB.GetEventFailed, timeout=1E-06
          SC_DTC_FRCinchMotorPlusSCB_ResetEventDebounceStatus: operation=DTC_FRCinchMotorPlusSCB.ResetEventDebounceStatus, timeout=1E-06
          SC_DTC_FRCinchMotorPlusSCB_SetEventStatus: operation=DTC_FRCinchMotorPlusSCB.SetEventStatus, timeout=1E-06
          SC_DTC_FRCinchMotorPlusSCG_GetEventFailed: operation=DTC_FRCinchMotorPlusSCG.GetEventFailed, timeout=1E-06
          SC_DTC_FRCinchMotorPlusSCG_ResetEventDebounceStatus: operation=DTC_FRCinchMotorPlusSCG.ResetEventDebounceStatus, timeout=1E-06
          SC_DTC_FRCinchMotorPlusSCG_SetEventStatus: operation=DTC_FRCinchMotorPlusSCG.SetEventStatus, timeout=1E-06
          SC_IoHwAb_HbrModCtrl_Hbr_SetMod: operation=IoHwAb_HbrModCtrl.Hbr_SetMod, timeout=0
          SC_IoHwAb_HbrPwm_Hbr_SetDuty: operation=IoHwAb_HbrPwm.Hbr_SetDuty, timeout=0
          SC_IoHwAb_IoDiagHbr_Hbr_Get: operation=IoHwAb_IoDiagHbr.Hbr_Get, timeout=0
  swc implementation SuctnDoor_DD_Implementation: behavior=SuctnDoor_DD_InternalBehavior
    code-descriptors:
      code Default: artifact-descriptors=autosar-engineering-object={short-label=Default, category=SWSRC}
package /UAES/ASW/Units
  unit NoUnit: factor-si-to-unit=1, offset-si-to-unit=0
